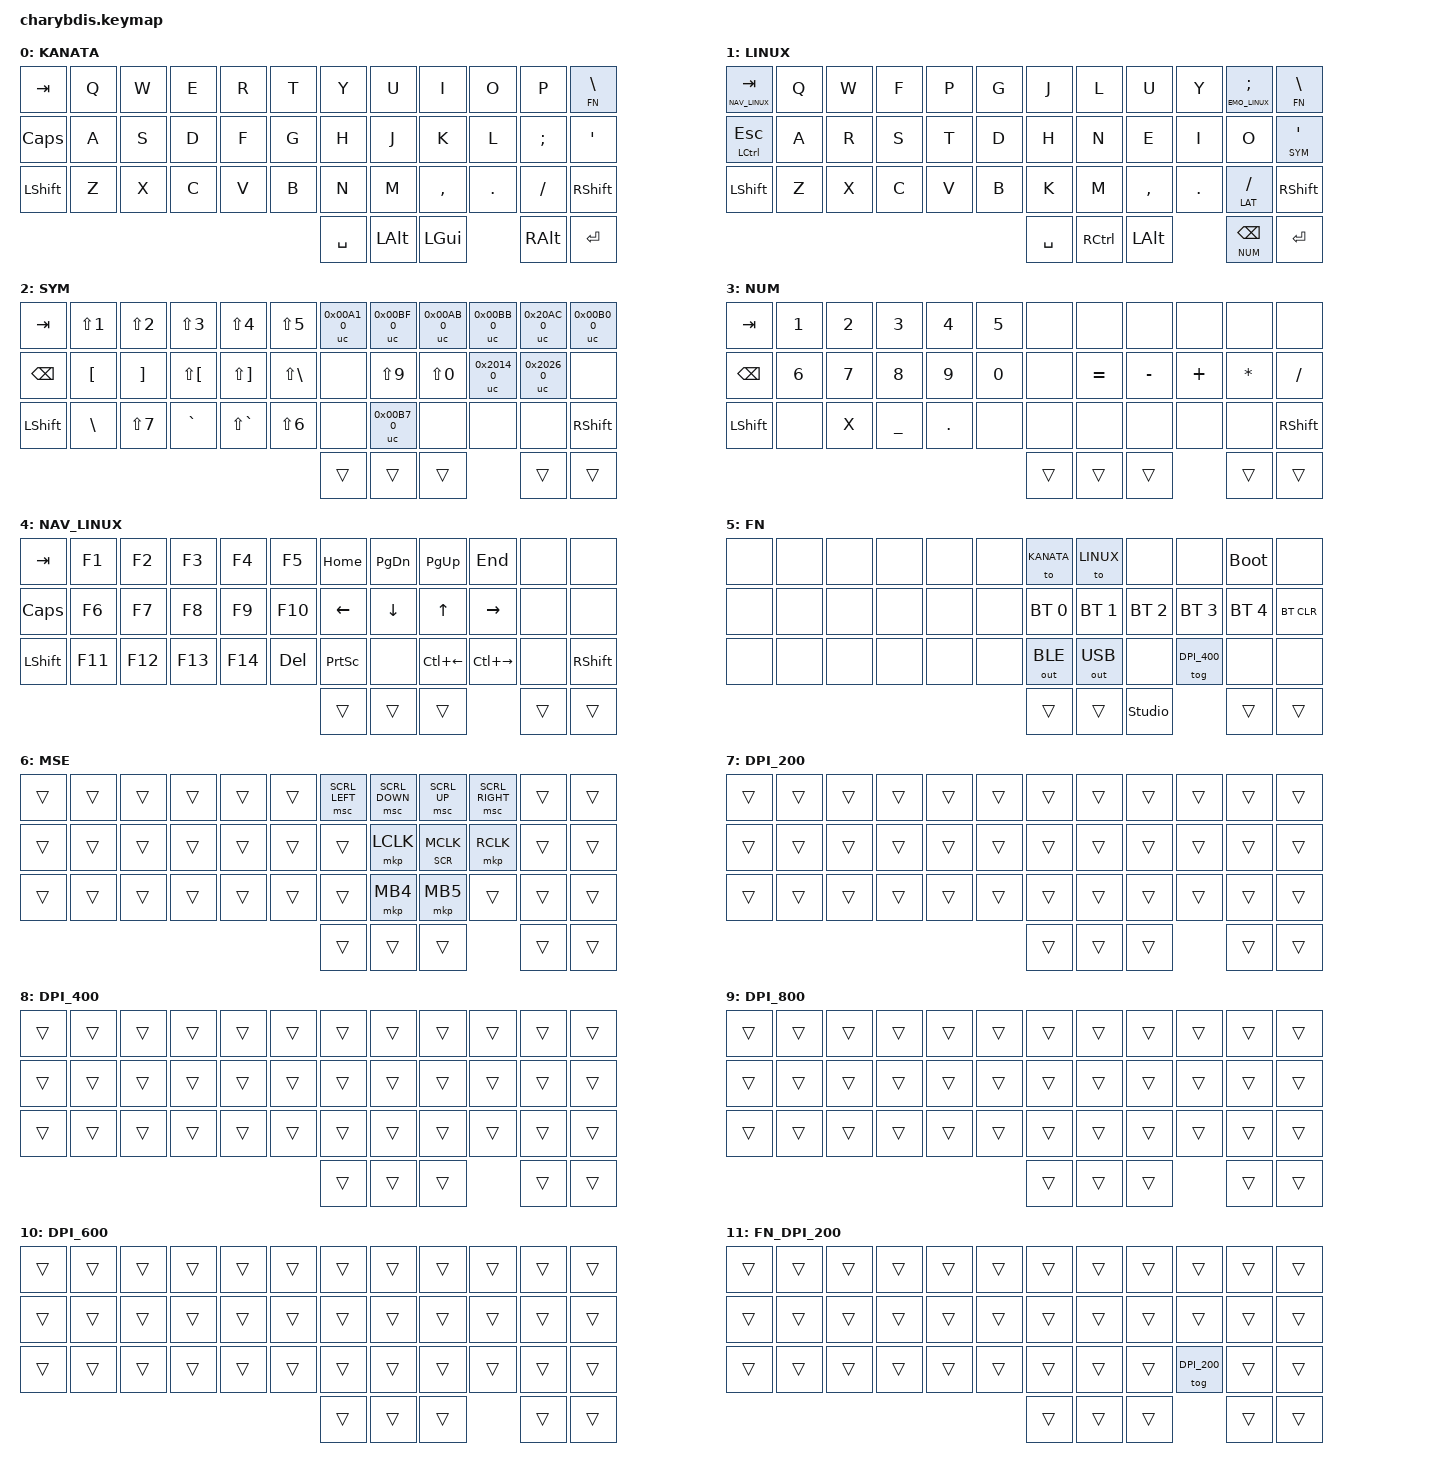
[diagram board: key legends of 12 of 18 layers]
#include <behaviors.dtsi>
#include <dt-bindings/zmk/keys.h>
#include <dt-bindings/zmk/bt.h>
#include <dt-bindings/zmk/outputs.h>
#include <dt-bindings/zmk/mouse.h>
#include <behaviors/unicode.dtsi>
#define KANATA 0
#define LINUX 1
#define SYM 2
#define NUM 3
#define NAV_LINUX 4
#define FN 5
#define MSE 6
#define DPI_200 7
#define DPI_400 8
#define DPI_800 9
#define DPI_600 10
#define FN_DPI_200 11
#define FN_DPI_400 12
#define FN_DPI_800 13
#define FN_DPI_600 14
#define SCR 15
#define EMO_LINUX 16
#define LAT 17

&lt {
    flavor = "hold-preferred";
    tapping-term-ms = <200>;
};

&uc {
    default-mode = <UC_MODE_LINUX>;
    minimum-length = <4>;
};

/ {
    behaviors {
        dpi_800_to_200: dpi_800_to_200 {
            compatible = "zmk,behavior-macro";
            #binding-cells = <0>;
            tap-ms = <0>;
            wait-ms = <0>;
            bindings = <&tog DPI_800>, <&tog DPI_200>;
        };

        dpi_400_to_600: dpi_400_to_600 {
            compatible = "zmk,behavior-macro";
            #binding-cells = <0>;
            tap-ms = <0>;
            wait-ms = <0>;
            bindings = <&tog DPI_400>, <&tog DPI_600>;
        };

        dpi_600_to_800: dpi_600_to_800 {
            compatible = "zmk,behavior-macro";
            #binding-cells = <0>;
            tap-ms = <0>;
            wait-ms = <0>;
            bindings = <&tog DPI_600>, <&tog DPI_800>;
        };

        typing_layer_tap: typing_layer_tap {
            compatible = "zmk,behavior-hold-tap";
            #binding-cells = <2>;
            flavor = "tap-preferred";
            tapping-term-ms = <300>;
            bindings = <&mo>, <&kp>;
            display-name = "Typing Layer-Tap";
        };

        caps_tap_ctrl: caps_tap_ctrl {
            compatible = "zmk,behavior-hold-tap";
            #binding-cells = <2>;
            flavor = "tap-preferred";
            tapping-term-ms = <200>;
            bindings = <&kp>, <&kp>;
            display-name = "Esc / Ctrl";
        };

        tmux_prefix: tmux_prefix {
            compatible = "zmk,behavior-hold-tap";
            #binding-cells = <2>;
            flavor = "balanced";
            tapping-term-ms = <200>;
            bindings = <&kp>, <&kp>;
            display-name = "RCtrl / Ctrl+G";
        };

        ltm: layer_tap_mouse {
            compatible = "zmk,behavior-hold-tap";
            #binding-cells = <2>;
            flavor = "tap-preferred";
            tapping-term-ms = <200>;
            bindings = <&mo>, <&mkp>;
            display-name = "Layer-Tap";
        };
    };

    conditional_layers {
        compatible = "zmk,conditional-layers";

        fn_dpi_200_layer {
            if-layers = <FN DPI_200>;
            then-layer = <FN_DPI_200>;
        };

        fn_dpi_400_layer {
            if-layers = <FN DPI_400>;
            then-layer = <FN_DPI_400>;
        };

        fn_dpi_800_layer {
            if-layers = <FN DPI_800>;
            then-layer = <FN_DPI_800>;
        };

        fn_dpi_600_layer {
            if-layers = <FN DPI_600>;
            then-layer = <FN_DPI_600>;
        };
    };

    keymap {
        compatible = "zmk,keymap";

        kanata_layer {
            label = "KANATA";
            bindings = <
&kp TAB &kp Q &kp W &kp E &kp R &kp T &kp Y &kp U &kp I &kp O &kp P &typing_layer_tap FN BSLH
&kp CAPS &kp A &kp S &kp D &kp F &kp G &kp H &kp J &kp K &kp L &kp SEMI &kp SQT
&kp LSHIFT &kp Z &kp X &kp C &kp V &kp B &kp N &kp M &kp COMMA &kp DOT &kp FSLH &kp RSHIFT
                                      &kp SPACE &kp LALT &kp LGUI &kp RALT &kp ENTER
            >;
        };

        linux_layer {
            label = "LINUX";
            bindings = <
&lt NAV_LINUX TAB &kp Q &kp W &kp F &kp P &kp G &kp J &kp L &kp U &kp Y &lt EMO_LINUX SEMI &typing_layer_tap FN BSLH
&caps_tap_ctrl LCTRL ESC &kp A &kp R &kp S &kp T &kp D &kp H &kp N &kp E &kp I &kp O &lt SYM SQT
&kp LSHIFT &kp Z &kp X &kp C &kp V &kp B &kp K &kp M &kp COMMA &kp DOT &lt LAT FSLH &kp RSHIFT
                                      &kp SPACE &kp RCTRL &kp LALT &lt NUM BSPC &kp ENTER
            >;
        };

        symbol_layer {
            label = "SYM";
            bindings = <
&kp TAB &kp LS(N1) &kp LS(N2) &kp LS(N3) &kp LS(N4) &kp LS(N5) &uc 0x00A1 0 &uc 0x00BF 0 &uc 0x00AB 0 &uc 0x00BB 0 &uc 0x20AC 0 &uc 0x00B0 0
&kp BSPC &kp LBKT &kp RBKT &kp LS(LBKT) &kp LS(RBKT) &kp LS(BSLH) &none &kp LS(N9) &kp LS(N0) &uc 0x2014 0 &uc 0x2026 0 &none
&kp LSHIFT &kp BSLH &kp LS(N7) &kp GRAVE &kp LS(GRAVE) &kp LS(N6) &none &uc 0x00B7 0 &none &none &none &kp RSHIFT
                                      &trans &trans &trans &trans &trans
            >;
        };

        num_layer {
            label = "NUM";
            bindings = <
&kp TAB &kp N1 &kp N2 &kp N3 &kp N4 &kp N5 &none &none &none &none &none &none
&kp BSPC &kp N6 &kp N7 &kp N8 &kp N9 &kp N0 &none &kp EQUAL &kp MINUS &kp PLUS &kp STAR &kp FSLH
&kp LSHIFT &none &kp X &kp UNDER &kp DOT &none &none &none &none &none &none &kp RSHIFT
                                      &trans &trans &trans &trans &trans
            >;
        };

        nav_linux_layer {
            label = "NAV_LINUX";
            bindings = <
&kp TAB &kp F1 &kp F2 &kp F3 &kp F4 &kp F5 &kp HOME &kp PG_DN &kp PG_UP &kp END &none &none
&kp CAPS &kp F6 &kp F7 &kp F8 &kp F9 &kp F10 &kp LEFT &kp DOWN &kp UP &kp RIGHT &none &none
&kp LSHIFT &kp F11 &kp F12 &kp F13 &kp F14 &kp DEL &kp PSCRN &none &kp LC(LEFT) &kp LC(RIGHT) &none &kp RSHIFT
                                      &trans &trans &trans &trans &trans
            >;
        };

        fn_layer {
            label = "FN";
            bindings = <
&none &none &none &none &none &none &to KANATA &to LINUX &none &none &bootloader &none
&none &none &none &none &none &none &bt BT_SEL 0 &bt BT_SEL 1 &bt BT_SEL 2 &bt BT_SEL 3 &bt BT_SEL 4 &bt BT_CLR
&none &none &none &none &none &none &out OUT_BLE &out OUT_USB &none &tog DPI_400 &none &none
                                      &trans &trans &studio_unlock &trans &trans
            >;
        };

        mouse_layer {
            label = "MSE";
            bindings = <
&trans &trans &trans &trans &trans &trans &msc SCRL_LEFT &msc SCRL_DOWN &msc SCRL_UP &msc SCRL_RIGHT &trans &trans
&trans &trans &trans &trans &trans &trans &trans &mkp LCLK &ltm SCR MCLK &mkp RCLK &trans &trans
&trans &trans &trans &trans &trans &trans &trans &mkp MB4 &mkp MB5 &trans &trans &trans
                                      &trans &trans &trans &trans &trans
            >;
        };

        dpi_200_layer {
            label = "DPI_200";
            bindings = <
&trans &trans &trans &trans &trans &trans &trans &trans &trans &trans &trans &trans
&trans &trans &trans &trans &trans &trans &trans &trans &trans &trans &trans &trans
&trans &trans &trans &trans &trans &trans &trans &trans &trans &trans &trans &trans
                                       &trans &trans &trans &trans &trans
            >;
        };

        dpi_400_layer {
            label = "DPI_400";
            bindings = <
&trans &trans &trans &trans &trans &trans &trans &trans &trans &trans &trans &trans
&trans &trans &trans &trans &trans &trans &trans &trans &trans &trans &trans &trans
&trans &trans &trans &trans &trans &trans &trans &trans &trans &trans &trans &trans
                                       &trans &trans &trans &trans &trans
            >;
        };

        dpi_800_layer {
            label = "DPI_800";
            bindings = <
&trans &trans &trans &trans &trans &trans &trans &trans &trans &trans &trans &trans
&trans &trans &trans &trans &trans &trans &trans &trans &trans &trans &trans &trans
&trans &trans &trans &trans &trans &trans &trans &trans &trans &trans &trans &trans
                                       &trans &trans &trans &trans &trans
            >;
        };

        dpi_600_layer {
            label = "DPI_600";
            bindings = <
&trans &trans &trans &trans &trans &trans &trans &trans &trans &trans &trans &trans
&trans &trans &trans &trans &trans &trans &trans &trans &trans &trans &trans &trans
&trans &trans &trans &trans &trans &trans &trans &trans &trans &trans &trans &trans
                                       &trans &trans &trans &trans &trans
            >;
        };

        fn_dpi_200_layer {
            label = "FN_DPI_200";
            bindings = <
&trans &trans &trans &trans &trans &trans &trans &trans &trans &trans &trans &trans
&trans &trans &trans &trans &trans &trans &trans &trans &trans &trans &trans &trans
&trans &trans &trans &trans &trans &trans &trans &trans &trans &tog DPI_200 &trans &trans
                                       &trans &trans &trans &trans &trans
            >;
        };

        fn_dpi_400_layer {
            label = "FN_DPI_400";
            bindings = <
&trans &trans &trans &trans &trans &trans &trans &trans &trans &trans &trans &trans
&trans &trans &trans &trans &trans &trans &trans &trans &trans &trans &trans &trans
&trans &trans &trans &trans &trans &trans &trans &trans &trans &dpi_400_to_600 &trans &trans
                                       &trans &trans &trans &trans &trans
            >;
        };

        fn_dpi_800_layer {
            label = "FN_DPI_800";
            bindings = <
&trans &trans &trans &trans &trans &trans &trans &trans &trans &trans &trans &trans
&trans &trans &trans &trans &trans &trans &trans &trans &trans &trans &trans &trans
&trans &trans &trans &trans &trans &trans &trans &trans &trans &dpi_800_to_200 &trans &trans
                                       &trans &trans &trans &trans &trans
            >;
        };

        fn_dpi_600_layer {
            label = "FN_DPI_600";
            bindings = <
&trans &trans &trans &trans &trans &trans &trans &trans &trans &trans &trans &trans
&trans &trans &trans &trans &trans &trans &trans &trans &trans &trans &trans &trans
&trans &trans &trans &trans &trans &trans &trans &trans &trans &dpi_600_to_800 &trans &trans
                                       &trans &trans &trans &trans &trans
            >;
        };

        scroll_layer {
            label = "SCR";
            bindings = <
&trans &trans &trans &trans &trans &trans &msc SCRL_LEFT &msc SCRL_DOWN &msc SCRL_UP &msc SCRL_RIGHT &trans &trans
&trans &trans &trans &trans &trans &trans &trans &mkp LCLK &ltm SCR MCLK &mkp RCLK &trans &trans
&trans &trans &trans &trans &trans &trans &trans &mkp MB4 &mkp MB5 &trans &trans &trans
                                      &trans &trans &trans &trans &trans
            >;
        };

        emoji_linux_layer {
            label = "EMO_LINUX";
            bindings = <
&none &uc 0x1F600 0 &uc 0x1F602 0 &uc 0x1F62D 0 &uc 0x1F634 0 &uc 0x1F914 0 &uc 0x1F60E 0 &uc 0x1F31D 0 &uc 0x1F31A 0 &uc 0x1F440 0 &uc 0x1F634 0 &none
&none &uc 0x2705 0 &uc 0x274C 0 &uc 0x2753 0 &uc 0x1F6A8 0 &uc 0x1F389 0 &uc 0x2728 0 &uc 0x1F680 0 &uc 0x1F525 0 &uc 0x1F4A1 0 &none &none
&none &uc 0x1F44C 0 &uc 0x1F44F 0 &uc 0x1F91D 0 &uc 0x1F44D 0 &uc 0x1F64F 0 &uc 0x1F496 0 &uc 0x1F388 0 &none &none &none &none
                                      &trans &trans &trans &trans &trans
            >;
        };

        latin_layer {
            label = "LAT";
            bindings = <
&none &uc 0x00E1 0x00C1 &uc 0x00E9 0x00C9 &uc 0x00E8 0x00C8 &uc 0x00E0 0x00C0 &uc 0x00EF 0x00CF &uc 0x00E6 0x00C6 &uc 0x0153 0x0152 &uc 0x00E2 0x00C2 &uc 0x00EB 0x00CB &none &none
&none &uc 0x00F1 0x00D1 &uc 0x00ED 0x00CD &uc 0x00EA 0x00CA &uc 0x00F6 0x00D6 &uc 0x00FC 0x00DC &uc 0x00F4 0x00D4 &uc 0x00EE 0x00CE &uc 0x00F9 0x00D9 &uc 0x00FB 0x00DB &uc 0x00FF 0x0178 &none
&kp LSHIFT &uc 0x00F3 0x00D3 &uc 0x00FA 0x00DA &uc 0x00DF 0x1E9E &uc 0x00E4 0x00C4 &uc 0x00EC 0x00CC &uc 0x00E7 0x00C7 &uc 0x00F2 0x00D2 &none &none &none &kp RSHIFT
                                      &trans &trans &trans &trans &trans
            >;
        };
    };
};
